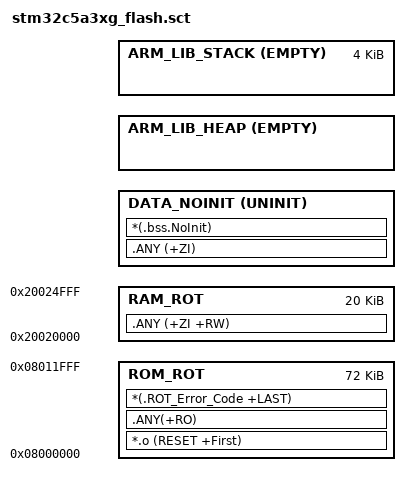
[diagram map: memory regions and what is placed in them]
#! armclang -E --target=arm-arm-none-eabi -mcpu=cortex-m33 -xc
; command above MUST be in first line (no comment above!)

; ******************************************************************************
; * @file    stm32c5a3xg_flash.sct
; * @brief   Linker File
; ******************************************************************************
; * @attention
; *
; * Copyright (c) 2026 STMicroelectronics.
; * All rights reserved.
; *
; * This software is licensed under terms that can be found in the LICENSE file
; * in the root directory of this software component.
; * If no LICENSE file comes with this software, it is provided AS-IS.
; *
; ******************************************************************************


/* Do not edit FLASH_xxxxxx definitions, updated by the provisioning scripts */
#define ROM_ROT_ADDRESS 0x8000000
#define ROM_ROT_SIZE 0x12000

/* RAM_ROT_xxxx definitions shall be aligned with SRAM_ROT_xxxx definitions of region_defs.h */
#define RAM_ROT_ADDRESS 0x20020000
#define RAM_ROT_SIZE 0x5000

#define __HEAP_SIZE 0x0
#define __STACK_SIZE 0x1000

ROM_ROT ROM_ROT_ADDRESS
{
  ROM_ROT ROM_ROT_ADDRESS ROM_ROT_SIZE
  {
    *.o (RESET +First)
    .ANY(+RO)
    *(.ROT_Error_Code +LAST) ; Explicitly place the .ROT_Error_Code section
  }

  RAM_ROT RAM_ROT_ADDRESS RAM_ROT_SIZE
  {
    .ANY (+ZI +RW)
  }

  /* Section .bss.NoInit */
  DATA_NOINIT +0 ALIGN 32 UNINIT {
    .ANY (+ZI)
    *(.bss.NoInit)
  }

  /* MSP */
  ARM_LIB_HEAP AlignExpr(+0, 8) EMPTY  __HEAP_SIZE
  {
  }

  ARM_LIB_STACK AlignExpr(+0, 8) EMPTY  __STACK_SIZE
  {
  }
}
